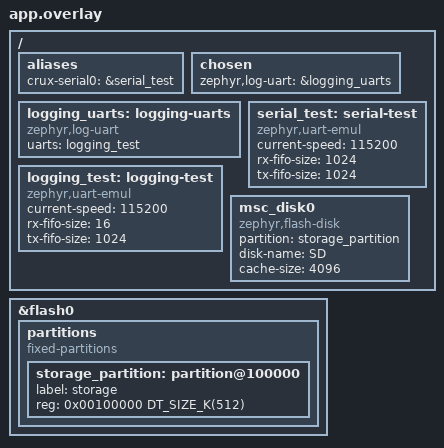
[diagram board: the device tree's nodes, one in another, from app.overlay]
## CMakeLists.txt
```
# SPDX-License-Identifier: Apache-2.0
# ADR-0004 phase 1b (Experimental): an application that starts the serial console with the first-account
# setup through the public composition interface <crux/cli_zephyr.h> and nothing private. It reaches Crux
# only through public targets (crux::access, crux::credential_store, crux::security_event, crux::cli,
# crux::cli_zephyr, crux::file_zephyr, crux::time) and includes no frozen header (<crux/serial.h>,
# <crux/thread.h>), no adapter header and no console header. The module builds the console and the event
# provider under CONFIG_CRUX_CLI_CONSOLE. The first account is NOT created in code: the test types `!setup`
# over an emulated UART, as a person would.
#
# Build it with the Mbed profile, as tests/native/cli_console/run.sh does:
#   -DEXTRA_CONF_FILE=../tls_offload_probe/mbed.conf;../management_composition/profile-psa.conf;../management_composition/mbed-threading.conf
#
# The TF-PSA-Crypto locks of the Mbed profile come from the module (CONFIG_CRUX_PSA_THREADING,
# Experimental), set by mbed-threading.conf above.
cmake_minimum_required(VERSION 3.20.0)
get_filename_component(CRUX_ROOT "${CMAKE_CURRENT_LIST_DIR}/../../.." ABSOLUTE)
list(APPEND ZEPHYR_EXTRA_MODULES "${CRUX_ROOT}")
find_package(Zephyr REQUIRED HINTS $ENV{ZEPHYR_BASE})
project(crux_cli_console LANGUAGES C)

if(NOT CONFIG_BOARD_NATIVE_SIM OR NOT CONFIG_FAKE_ENTROPY_NATIVE_SIM)
    message(FATAL_ERROR "This fixture is restricted to native_sim: its entropy is test-only")
endif()
# An unsatisfied dependency only warns in Kconfig and would build an application without the console.
if(NOT CONFIG_CRUX_CLI_CONSOLE OR NOT CONFIG_CRUX_CLI OR NOT CONFIG_CRUX_ACCESS OR NOT CONFIG_CRUX_SERIAL)
    message(FATAL_ERROR "The fixture needs CONFIG_CRUX_CLI_CONSOLE, CONFIG_CRUX_CLI, CONFIG_CRUX_ACCESS and CONFIG_CRUX_SERIAL")
endif()
# The service symbol selects Thread, Sync and Time (ADR-0004 C6): the fixture names none of them.
file(READ "${CMAKE_CURRENT_LIST_DIR}/prj.conf" fixture_conf)
if(fixture_conf MATCHES "CONFIG_CRUX_(THREAD|SYNC|TIME)[A-Z_]*=")
    message(FATAL_ERROR "prj.conf must not name a CONFIG_CRUX_THREAD, CONFIG_CRUX_SYNC or CONFIG_CRUX_TIME symbol: the service symbol selects them")
endif()

# The locks of the Mbed profile's core come from the module (CONFIG_CRUX_PSA_THREADING, set by mbed-threading.conf).
target_sources(app PRIVATE src/main.c)
target_link_libraries(app PRIVATE crux::access crux::credential_store crux::security_event crux::cli
    crux::cli_zephyr crux::file_zephyr crux::time)
target_compile_options(app PRIVATE -Wall -Wextra -Werror)
```

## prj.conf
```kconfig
# The serial console with its first-account setup, built by the Zephyr module under CONFIG_CRUX_CLI_CONSOLE
# (ADR-0004 phase 1b). The TLS stack and the PSA provider come from the profile's configuration: see
# CMakeLists.txt. The networking and TLS credential lines below are carried from the profile of
# tests/native/management_module, which the Mbed profile files expect; the fixture serves nothing.
CONFIG_ZTEST=y
CONFIG_ZTEST_VERIFY_RUN_ALL=n
CONFIG_MAIN_STACK_SIZE=32768
CONFIG_ZTEST_STACK_SIZE=32768
CONFIG_HEAP_MEM_POOL_SIZE=32768
CONFIG_STD_C17=y
# A Ztest image runs the simulated clock as fast as it can by default. The console's waits and the test's
# polling are in simulated time, so the image runs at real time, as tests/native/management_module does.
CONFIG_NATIVE_SIM_SLOWDOWN_TO_REAL_TIME=y

CONFIG_NETWORKING=y
CONFIG_NET_IPV4=y
CONFIG_NET_SOCKETS=y
CONFIG_NET_SOCKETS_OFFLOAD=y
CONFIG_NET_DRIVERS=y
CONFIG_NET_NATIVE_OFFLOADED_SOCKETS=y
CONFIG_ETH_NATIVE_TAP=n
CONFIG_NET_SOCKETS_SOCKOPT_TLS=y
CONFIG_TLS_CREDENTIALS=y
CONFIG_TLS_MAX_CREDENTIALS_NUMBER=4
CONFIG_NET_SOCKETS_TLS_MAX_CONTEXTS=6
CONFIG_ZVFS_OPEN_MAX=24
CONFIG_ZVFS_POLL_MAX=16
CONFIG_ZVFS_EVENTFD=y

# Test-only on native_sim. See docs/psa-crypto-design.md.
CONFIG_ENTROPY_GENERATOR=y
CONFIG_HWINFO=y


CONFIG_FILE_SYSTEM=y
CONFIG_FILE_SYSTEM_MKFS=y
CONFIG_FAT_FILESYSTEM_ELM=y
CONFIG_FS_FATFS_LFN=y
CONFIG_FS_FATFS_LFN_MODE_STACK=y
CONFIG_FS_FATFS_MAX_LFN=127
CONFIG_FS_FATFS_MOUNT_MKFS=n
CONFIG_FS_FATFS_REENTRANT=y
CONFIG_FS_FATFS_NUM_FILES=6
CONFIG_DISK_DRIVERS=y
CONFIG_DISK_DRIVER_FLASH=y
CONFIG_CRUX_FILE_FATFS_SIMULATOR=y

# The Crux Logging provider, on the emulated UART it accepts on native_sim.
CONFIG_CRUX_LOGGING=y
CONFIG_SERIAL=y
CONFIG_EMUL=y
CONFIG_UART_EMUL=y
CONFIG_LOG=y
CONFIG_LOG_MODE_DEFERRED=y
CONFIG_LOG_MODE_OVERFLOW=n
CONFIG_LOG_BLOCK_IN_THREAD=n
CONFIG_LOG_PROCESS_THREAD=y
CONFIG_LOG_PROCESS_THREAD_STACK_SIZE=2048
CONFIG_LOG_PROCESS_THREAD_CUSTOM_PRIORITY=y
CONFIG_LOG_PROCESS_THREAD_PRIORITY=14
CONFIG_LOG_BUFFER_SIZE=4096
CONFIG_LOG_MAX_LEVEL=4
CONFIG_LOG_RUNTIME_FILTERING=n
CONFIG_LOG_BACKEND_UART=y
CONFIG_LOG_BACKEND_NATIVE_POSIX=n
CONFIG_LOG_BACKEND_UART_ASYNC=n
CONFIG_LOG_PRINTK=n
CONFIG_THREAD_MONITOR=y
CONFIG_THREAD_NAME=y
CONFIG_SHELL_LOG_BACKEND=n

# The service symbols: CRUX_ACCESS (which selects the credential store, the security events, Thread, Sync and
# Time, ADR-0004 C6), the command line and its console. CRUX_CLI needs CRUX_SERIAL and CRUX_THREAD, and an
# image names CRUX_SERIAL itself (CRUX_THREAD comes with CRUX_ACCESS).
CONFIG_CRUX_ACCESS=y
CONFIG_CRUX_SERIAL=y
CONFIG_CRUX_CLI=y
CONFIG_CRUX_CLI_CONSOLE=y
CONFIG_UART_INTERRUPT_DRIVEN=y
CONFIG_UART_USE_RUNTIME_CONFIGURE=y
# No Zephyr shell on any UART: the console owns the one named by crux-serial0 (and the module refuses a shell
# on it).
CONFIG_SHELL=n
CONFIG_MINIMAL_LIBC=y
```

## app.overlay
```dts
/* SPDX-License-Identifier: Apache-2.0 */
/* A disk on the flash simulator, backed by a host file, so that it outlives each process. */
/delete-node/ &storage_partition;

&flash0 {
    partitions {
        compatible = "fixed-partitions";
        #address-cells = <1>;
        #size-cells = <1>;

        storage_partition: partition@100000 {
            label = "storage";
            reg = <0x00100000 DT_SIZE_K(512)>;
        };
    };
};

/ {
    aliases { crux-serial0 = &serial_test; };
    chosen { zephyr,log-uart = &logging_uarts; };
    logging_uarts: logging-uarts {
        compatible = "zephyr,log-uart";
        uarts = <&logging_test>;
    };
    /* The console's UART: the test thread types into its receive side and reads its transmit side. */
    serial_test: serial-test {
        compatible = "zephyr,uart-emul";
        current-speed = <115200>;
        rx-fifo-size = <1024>;
        tx-fifo-size = <1024>;
        status = "okay";
    };
    logging_test: logging-test {
        compatible = "zephyr,uart-emul";
        current-speed = <115200>;
        rx-fifo-size = <16>;
        tx-fifo-size = <1024>;
        status = "okay";
    };
    msc_disk0 {
        status = "okay";
        compatible = "zephyr,flash-disk";
        partition = <&storage_partition>;
        disk-name = "SD";
        cache-size = <4096>;
    };
};
```

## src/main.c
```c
/*
 * ADR-0004 phase 1b. The serial console with its first-account setup, started through the public
 * composition interface <crux/cli_zephyr.h>, on real PSA providers, a real FatFs on a simulated
 * disk and the Crux Logging provider. The first account is not created in code: the test types
 * `!setup` into an emulated UART, as a person would at a terminal, and reads the console's
 * replies. This is the first run of the console in any image. Test only: the entropy is
 * test-only. The file includes only public headers: no <crux/serial.h>, no <crux/thread.h>, no
 * adapter and no console header.
 */
#include <crux/access.h>
#include <crux/cli.h>
#include <crux/cli_zephyr.h>
#include <crux/credential_store.h>
#include <crux/file_zephyr.h>
#include <crux/security_event.h>
#include <crux/time.h>

#include <ff.h>
#include <string.h>
#include <zephyr/drivers/serial/uart_emul.h>
#include <zephyr/fs/fs.h>
#include <zephyr/kernel.h>
#include <zephyr/ztest.h>

enum { ROOT_SLOT_A = 1, ROOT_SLOT_B = 2 };
#define MOUNT_POINT "/SD:"
#define DISK_NAME "SD:"
#define PATH_SLOT_A MOUNT_POINT "/secure-a"
#define PATH_SLOT_B MOUNT_POINT "/secure-b"
#define ADMIN "admin"
#define ADMIN_PASSWORD "console test password"
#define WRONG_PASSWORD "this is the wrong password"
/* The first eight bytes of each, which no prompt or reply of the console contains. */
#define ADMIN_PASSWORD_START "console "
#define WRONG_PASSWORD_START "this is "
/* The role of the first account: it holds access.manage, as the console's setup requires. */
#define SETUP_ROLE "administrator"

static const char *const admin_permissions[] = {CRUX_ACCESS_PERMISSION_MANAGE};
static const char *const guest_permissions[] = {"guest.only"};
static const crux_access_role_t roles[] = {
    {"guest", guest_permissions, ARRAY_SIZE(guest_permissions)},
    {SETUP_ROLE, admin_permissions, ARRAY_SIZE(admin_permissions)},
};
static const crux_access_policy_t policy = {roles, ARRAY_SIZE(roles), 15u * 60u, 8u * 3600u, NULL};

static FATFS fat;
static struct fs_mount_t mount = {
    .type = FS_FATFS,
    .mnt_point = MOUNT_POINT,
    .fs_data = &fat,
    .flags = FS_MOUNT_FLAG_NO_FORMAT,
};
static const struct device *const console_uart = DEVICE_DT_GET(DT_NODELABEL(serial_test));

static bool directory_ready(const char *path)
{
    int result = fs_mkdir(path);
    return result == 0 || result == -EEXIST;
}

static bool medium_ready(void)
{
    if (fs_mount(&mount) != 0) {
        if (fs_mkfs(FS_FATFS, (uintptr_t)DISK_NAME, NULL, 0) != 0 || fs_mount(&mount) != 0) {
            return false;
        }
    }
    return directory_ready(PATH_SLOT_A) && directory_ready(PATH_SLOT_B) &&
           crux_file_zephyr_bind_root(ROOT_SLOT_A, PATH_SLOT_A) == CRUX_FILE_OK &&
           crux_file_zephyr_bind_root(ROOT_SLOT_B, PATH_SLOT_B) == CRUX_FILE_OK;
}

/* What the console has written, not yet consumed by an expectation. */
static char capture[2048];
static size_t captured;

static void drain(void)
{
    uint8_t chunk[64];
    uint32_t got;
    while ((got = uart_emul_get_tx_data(console_uart, chunk, sizeof(chunk))) > 0u) {
        zassert_true(captured + got < sizeof(capture), "the console wrote too much");
        memcpy(&capture[captured], chunk, got);
        captured += got;
        capture[captured] = '\0';
        /* A password is read without echo: neither a whole one nor its first eight bytes, which an
         * echo that stopped early would show, reaches the transmit side. */
        zassert_is_null(strstr(capture, ADMIN_PASSWORD), "a password was echoed");
        zassert_is_null(strstr(capture, WRONG_PASSWORD), "a password was echoed");
        zassert_is_null(strstr(capture, ADMIN_PASSWORD_START), "password start echoed");
        zassert_is_null(strstr(capture, WRONG_PASSWORD_START), "password start echoed");
    }
}

/* Waits for the console to write `text`, then drops everything up to and including it. */
static void expect(const char *text)
{
    for (int attempt = 0; attempt < 1000; ++attempt) {
        drain();
        char *found = strstr(capture, text);
        if (found != NULL) {
            size_t consumed = (size_t)(found - capture) + strlen(text);
            memmove(capture, &capture[consumed], captured - consumed + 1u);
            captured -= consumed;
            return;
        }
        k_msleep(10);
    }
    zassert_unreachable("the console did not write \"%s\"; it wrote \"%s\"", text, capture);
}

/* Waits for the console to write `text` as the very first thing since the last expectation:
 * nothing may come before it. */
static void expect_first(const char *text)
{
    for (int attempt = 0; attempt < 1000; ++attempt) {
        drain();
        if (captured >= strlen(text)) {
            zassert_equal(strncmp(capture, text, strlen(text)), 0, "first output: %s", capture);
            memmove(capture, &capture[strlen(text)], captured - strlen(text) + 1u);
            captured -= strlen(text);
            return;
        }
        k_msleep(10);
    }
    zassert_unreachable("the console did not write \"%s\"; it wrote \"%s\"", text, capture);
}

/* Types a line as a terminal does: the bytes and a carriage return. */
static void type_line(const char *text)
{
    char line[96];
    size_t length = strlen(text);
    zassert_true(length + 1u < sizeof(line));
    memcpy(line, text, length);
    line[length] = '\r';
    size_t sent = length + 1u;
    zassert_equal(uart_emul_put_rx_data(console_uart, (const uint8_t *)line, sent), sent);
}

static void *start_services_and_console(void)
{
    zassert_true(device_is_ready(console_uart));
    /* The order of docs/management-in-a-product.md, as far as the console needs it. */
    zassert_equal(crux_security_event_init(NULL, 0), CRUX_OK);
    zassert_equal(crux_realtime_init(), CRUX_OK);
    zassert_true(medium_ready());
    crux_credential_result_t store = crux_credential_start(ROOT_SLOT_A, ROOT_SLOT_B);
    zassert_true(store == CRUX_CREDENTIAL_OK || store == CRUX_CREDENTIAL_ERR_UNUSABLE);
    zassert_equal(crux_access_init(&policy), CRUX_ACCESS_OK);
    zassert_equal(crux_security_event_start(), CRUX_OK);
    /* The product's command tables: none. The built-in commands (help, logout, passwd, account
     * list) remain. */
    zassert_equal(crux_cli_init(NULL, NULL, 0u), CRUX_CLI_OK);
    static const crux_cli_serial_config_t console = {.setup_role = SETUP_ROLE};
    zassert_equal(crux_cli_serial_start(&console), CRUX_CLI_OK);
    /* A second call changes nothing. */
    zassert_equal(crux_cli_serial_start(&console), CRUX_CLI_OK);
    return NULL;
}

ZTEST_SUITE(cli_console, NULL, start_services_and_console, NULL, NULL, NULL);

ZTEST(cli_console, test_01_the_start_refuses_a_missing_argument)
{
    static const crux_cli_serial_config_t no_role = {.setup_role = NULL};
    zassert_equal(crux_cli_serial_start(NULL), CRUX_CLI_ERR_INVALID_ARGUMENT);
    zassert_equal(crux_cli_serial_start(&no_role), CRUX_CLI_ERR_INVALID_ARGUMENT);
}

ZTEST(cli_console, test_02_the_login_prompt_comes_first_and_an_unknown_user_is_refused)
{
    /* Nothing about the device is written before the prompt. */
    expect_first("login: ");
    type_line("nobody");
    expect("password: ");
    type_line(WRONG_PASSWORD);
    expect("login failed");
    expect("login: ");
}

ZTEST(cli_console, test_03_setup_creates_the_first_account_from_typed_input)
{
    type_line("!setup");
    expect("new user: ");
    type_line(ADMIN);
    expect("password: ");
    type_line(ADMIN_PASSWORD);
    expect("repeat: ");
    type_line(ADMIN_PASSWORD);
    expect("account created");
    expect("login: ");
}

ZTEST(cli_console, test_04_a_second_setup_is_refused_because_an_account_exists)
{
    type_line("!setup");
    expect("new user: ");
    type_line("second");
    expect("password: ");
    type_line(ADMIN_PASSWORD);
    expect("repeat: ");
    type_line(ADMIN_PASSWORD);
    expect("setup not available");
    expect("login: ");
}

ZTEST(cli_console, test_05_a_login_as_the_new_account_runs_a_command_and_logs_out)
{
    type_line(ADMIN);
    expect("password: ");
    type_line(ADMIN_PASSWORD);
    expect("> ");
    type_line("help");
    expect("logout");
    expect("> ");
    type_line("logout");
    expect("login: ");
}
```
